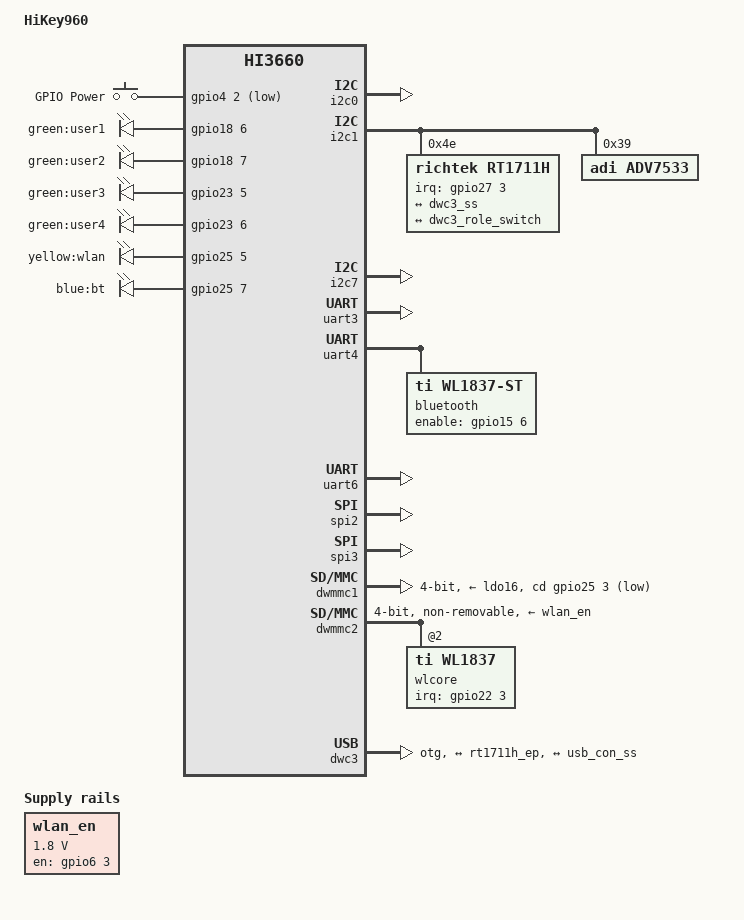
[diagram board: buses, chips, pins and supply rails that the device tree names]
/dts-v1/;
#include "hi3660.dtsi"
#include "hikey960-pinctrl.dtsi"
#include <dt-bindings/gpio/gpio.h>
#include <dt-bindings/input/input.h>
#include <dt-bindings/interrupt-controller/irq.h>
#include <dt-bindings/usb/pd.h>
/ {
	model = "HiKey960";
	compatible = "hisilicon,hi3660-hikey960", "hisilicon,hi3660";
	aliases {
		mshc1 = &dwmmc1;
		mshc2 = &dwmmc2;
		serial0 = &uart0;
		serial1 = &uart1;
		serial2 = &uart2;
		serial3 = &uart3;
		serial4 = &uart4;
		serial5 = &uart5;
		serial6 = &uart6;
	};
	chosen {
		stdout-path = "serial6:115200n8";
	};
	memory@0 {
		device_type = "memory";
		reg = <0x0 0x0 0x0 0x0>;
	};
	reserved-memory {
		#address-cells = <2>;
		#size-cells = <2>;
		ranges;
		ramoops@32000000 {
			compatible = "ramoops";
			reg = <0x0 0x32000000 0x0 0x00100000>;
			record-size = <0x00020000>;
			console-size = <0x00020000>;
			ftrace-size = <0x00020000>;
		};
	};
	reboot-mode-syscon@32100000 {
		compatible = "syscon", "simple-mfd";
		reg = <0x0 0x32100000 0x0 0x00001000>;
		reboot-mode {
			compatible = "syscon-reboot-mode";
			offset = <0x0>;
			mode-normal = <0x77665501>;
			mode-bootloader = <0x77665500>;
			mode-recovery = <0x77665502>;
		};
	};
	keys {
		compatible = "gpio-keys";
		pinctrl-names = "default";
		pinctrl-0 = <&pwr_key_pmx_func &pwr_key_cfg_func>;
		key-power {
			wakeup-source;
			gpios = <&gpio4 2 GPIO_ACTIVE_LOW>;
			label = "GPIO Power";
			linux,code = <KEY_POWER>;
		};
	};
	leds {
		compatible = "gpio-leds";
		led-user-1 {
			label = "green:user1";
			gpios = <&gpio18 6 0>;
			linux,default-trigger = "heartbeat";
		};
		led-user-2 {
			label = "green:user2";
			gpios = <&gpio18 7 0>;
			linux,default-trigger = "none";
		};
		led-user-3 {
			label = "green:user3";
			gpios = <&gpio23 5 0>;
			linux,default-trigger = "mmc0";
		};
		led-user-4 {
			label = "green:user4";
			gpios = <&gpio23 6 0>;
			panic-indicator;
			linux,default-trigger = "none";
		};
		led-wlan {
			label = "yellow:wlan";
			gpios = <&gpio25 5 0>;
			linux,default-trigger = "phy0tx";
			default-state = "off";
		};
		led-bt {
			label = "blue:bt";
			gpios = <&gpio25 7 0>;
			linux,default-trigger = "hci0-power";
			default-state = "off";
		};
	};
	pmic: pmic@fff34000 {
		compatible = "hisilicon,hi6421v530-pmic";
		reg = <0x0 0xfff34000 0x0 0x1000>;
		interrupt-controller;
		#interrupt-cells = <2>;
		regulators {
			ldo3: LDO3 {  
				regulator-name = "VOUT3_1V85";
				regulator-min-microvolt = <1800000>;
				regulator-max-microvolt = <2200000>;
				regulator-enable-ramp-delay = <120>;
			};
			ldo9: LDO9 {  
				regulator-name = "VOUT9_1V8_2V95";
				regulator-min-microvolt = <1750000>;
				regulator-max-microvolt = <3300000>;
				regulator-enable-ramp-delay = <240>;
			};
			ldo11: LDO11 {  
				regulator-name = "VOUT11_1V8_2V95";
				regulator-min-microvolt = <1750000>;
				regulator-max-microvolt = <3300000>;
				regulator-enable-ramp-delay = <240>;
			};
			ldo15: LDO15 {  
				regulator-name = "VOUT15_3V0";
				regulator-min-microvolt = <1750000>;
				regulator-max-microvolt = <3000000>;
				regulator-boot-on;
				regulator-always-on;
				regulator-enable-ramp-delay = <120>;
			};
			ldo16: LDO16 {  
				regulator-name = "VOUT16_2V95";
				regulator-min-microvolt = <1750000>;
				regulator-max-microvolt = <3000000>;
				regulator-enable-ramp-delay = <360>;
			};
		};
	};
	wlan_en: wlan-en-1-8v {
		compatible = "regulator-fixed";
		regulator-name = "wlan-en-regulator";
		regulator-min-microvolt = <1800000>;
		regulator-max-microvolt = <1800000>;
		gpio = <&gpio6 3 0>;
		startup-delay-us = <70000>;
		enable-active-high;
	};
	firmware {
		optee {
			compatible = "linaro,optee-tz";
			method = "smc";
		};
	};
};
&gpio0 {
	gpio-line-names =
		"",
		"TP901",  
		"[PMU0_SSI]",
		"[PMU1_SSI]",
		"[PMU2_SSI]",
		"[PMU0_CLKOUT]",
		"[JTAG_TCK]",
		"[JTAG_TMS]";
};
&gpio1 {
	gpio-line-names =
		"[JTAG_TRST_N]",
		"[JTAG_TDI]",
		"[JTAG_TDO]",
		"NC", "NC",
		"[I2C3_SCL]",
		"[I2C3_SDA]",
		"NC";
};
&gpio2 {
	gpio-line-names =
		"NC", "NC", "NC",
		"GPIO-J",  
		"GPIO_020_HDMI_SEL",
		"GPIO-L",  
		"GPIO_022_UFSBUCK_INT_N",
		"GPIO-G";  
};
&gpio3 {
	gpio-line-names =
		"[CSI0_MCLK]",  
		"[CSI1_MCLK]",  
		"NC",
		"[I2C2_SCL]",  
		"[I2C2_SDA]",  
		"[I2C3_SCL]",  
		"[I2C3_SDA]",  
		"NC";
};
&gpio4 {
	gpio-line-names =
		"NC", "NC",
		"PWR_BTN_N",  
		"GPIO_035_PMU2_EN",
		"GPIO_036_USB_HUB_RESET",
		"NC", "NC", "NC";
};
&gpio5 {
	gpio-line-names =
		"GPIO-H",  
		"GPIO_041_HDMI_PD",
		"TP904",  
		"TP905",  
		"NC", "NC",
		"GPIO_046_HUB_VDD33_EN",
		"GPIO_047_PMU1_EN";
};
&gpio6 {
	gpio-line-names =
		"NC", "NC", "NC",
		"GPIO_051_WIFI_EN",
		"GPIO-I",  
		"[SD_DAT1]",  
		"[SD_DAT2]",  
		"[UART1_RXD]";  
};
&gpio7 {
	gpio-line-names =
		"[UART1_TXD]",  
		"[UART0_CTS]",  
		"[UART0_RTS]",  
		"[UART0_RXD]",  
		"[UART0_TXD]",  
		"[SOC_BT_UART4_CTS_N]",
		"[SOC_BT_UART4_RTS_N]",
		"[SOC_BT_UART4_RXD]";
};
&gpio8 {
	gpio-line-names =
		"[SOC_BT_UART4_TXD]",
		"NC",
		"[PMU_HKADC_SSI]",
		"NC",
		"GPIO_068_SEL",
		"NC", "NC", "NC";
};
&gpio9 {
	gpio-line-names =
		"NC", "NC", "NC",
		"GPIO-K",  
		"NC", "NC", "NC", "NC";
};
&gpio10 {
	gpio-line-names = "NC", "NC", "NC", "NC", "NC", "NC", "NC", "NC";
};
&gpio11 {
	gpio-line-names =
		"NC",
		"[PCIE_PERST_N]",
		"NC", "NC", "NC", "NC", "NC", "NC";
};
&gpio12 {
	gpio-line-names = "NC", "NC", "NC", "", "", "", "", "NC";
};
&gpio13 {
	gpio-line-names = "NC", "NC", "NC", "NC", "NC", "NC", "NC", "NC";
};
&gpio14 {
	gpio-line-names = "NC", "NC", "NC", "NC", "NC", "NC", "NC", "NC";
};
&gpio15 {
	gpio-line-names =
		"NC", "NC", "NC", "NC", "NC", "NC",
		"GPIO_126_BT_EN",
		"TP902";  
};
&gpio16 {
	gpio-line-names = "", "", "", "", "", "", "", "";
};
&gpio17 {
	gpio-line-names = "", "", "", "", "", "", "", "";
};
&gpio18 {
	gpio-line-names =
		"[UFS_REF_CLK]",
		"[UFS_RST_N]",
		"[SPI1_SCLK]",  
		"[SPI1_DIN]",  
		"[SPI1_DOUT]",  
		"[SPI1_CS]",  
		"GPIO_150_USER_LED1",
		"GPIO_151_USER_LED2";
};
&gpio19 {
	gpio-line-names = "NC", "NC", "NC", "NC", "", "", "", "";
};
&gpio20 {
	gpio-line-names =
		"[SD_CLK]",
		"[SD_CMD]",
		"[SD_DATA0]",
		"[SD_DATA1]",
		"[SD_DATA2]",
		"[SD_DATA3]",
		"", "";
};
&gpio21 {
	gpio-line-names =
		"[WL_SDIO_CLK]",
		"[WL_SDIO_CMD]",
		"[WL_SDIO_DATA0]",
		"[WL_SDIO_DATA1]",
		"[WL_SDIO_DATA2]",
		"[WL_SDIO_DATA3]",
		"", "";
};
&gpio22 {
	gpio-line-names =
		"[GPIO_176_PMU_PWR_HOLD]",
		"NA",
		"[SYSCLK_EN]",
		"GPIO_179_WL_WAKEUP_AP",
		"GPIO_180_HDMI_INT",
		"NA",
		"GPIO-F",  
		"[I2C0_SCL]";  
};
&gpio23 {
	gpio-line-names =
		"[I2C0_SDA]",  
		"[I2C1_SCL]",  
		"[I2C1_SDA]",  
		"[I2C1_SCL]",  
		"[I2C1_SDA]",  
		"GPIO_189_USER_LED3",
		"GPIO_190_USER_LED4",
		"";
};
&gpio24 {
	gpio-line-names =
		"[PCM_DI]",  
		"[PCM_DO]",  
		"[PCM_CLK]",  
		"[PCM_FS]",  
		"[GPIO_196_I2S2_DI]",
		"[GPIO_197_I2S2_DO]",
		"[GPIO_198_I2S2_XCLK]",
		"[GPIO_199_I2S2_XFS]";
};
&gpio25 {
	gpio-line-names =
		"NC",
		"NC",
		"GPIO_202_VBUS_TYPEC",
		"GPIO_203_SD_DET",
		"GPIO_204_PMU12_IRQ_N",
		"GPIO_205_WIFI_ACTIVE",
		"GPIO_206_USBSW_SEL",
		"GPIO_207_BT_ACTIVE";
};
&gpio26 {
	gpio-line-names =
		"GPIO-A",  
		"GPIO-B",  
		"GPIO-C",  
		"GPIO-D",  
		"GPIO-E",  
		"[PCIE_CLKREQ_N]",
		"[PCIE_WAKE_N]",
		"[SPI0_CLK]";  
};
&gpio27 {
	gpio-line-names =
		"[SPI0_DIN]",  
		"[SPI0_DOUT]",  
		"[SPI0_CS]",  
		"GPIO_219_CC_INT",
		"NC",
		"NC",
		"[PMU_INT]",
		"";
};
&gpio28 {
	gpio-line-names =
		"", "", "", "", "", "", "", "";
};
&i2c0 {
	label = "LS-I2C0";
	status = "okay";
};
&i2c1 {
	status = "okay";
	rt1711h: rt1711h@4e {
		compatible = "richtek,rt1711h";
		reg = <0x4e>;
		status = "okay";
		interrupt-parent = <&gpio27>;
		interrupts = <3 IRQ_TYPE_LEVEL_LOW>;
		pinctrl-names = "default";
		pinctrl-0 = <&usb_cfg_func>;
		usb_con: connector {
			compatible = "usb-c-connector";
			label = "USB-C";
			data-role = "dual";
			power-role = "dual";
			try-power-role = "sink";
			source-pdos = <PDO_FIXED(5000, 500, PDO_FIXED_USB_COMM)>;
			sink-pdos = <PDO_FIXED(5000, 500, PDO_FIXED_USB_COMM)
				PDO_VAR(5000, 5000, 1000)>;
			op-sink-microwatt = <10000000>;
			ports {
				#address-cells = <1>;
				#size-cells = <0>;
				port@1 {
					reg = <1>;
					usb_con_ss: endpoint {
						remote-endpoint = <&dwc3_ss>;
					};
				};
			};
		};
		port {
			#address-cells = <1>;
			#size-cells = <0>;
			rt1711h_ep: endpoint@0 {
				reg = <0>;
				remote-endpoint = <&dwc3_role_switch>;
			};
		};
	};
	adv7533: adv7533@39 {
		status = "okay";
		compatible = "adi,adv7533";
		reg = <0x39>;
		adi,dsi-lanes = <4>;
		ports {
			#address-cells = <1>;
			#size-cells = <0>;
			port@0 {
				reg = <0>;
			};
			port@1 {
				reg = <1>;
			};
		};
	};
};
&i2c7 {
	label = "LS-I2C1";
	status = "okay";
};
&uart3 {
	label = "LS-UART0";
	status = "okay";
};
&uart4 {
	status = "okay";
	bluetooth {
		compatible = "ti,wl1837-st";
		enable-gpios = <&gpio15 6 GPIO_ACTIVE_HIGH>;
		max-speed = <3000000>;
	};
};
&uart6 {
	label = "LS-UART1";
	status = "okay";
};
&spi2 {
	label = "LS-SPI0";
	status = "okay";
};
&spi3 {
	label = "HS-SPI1";
	status = "okay";
};
&dwmmc1 {
	bus-width = <0x4>;
	cap-sd-highspeed;
	sd-uhs-sdr12;
	sd-uhs-sdr25;
	sd-uhs-sdr50;
	sd-uhs-sdr104;
	disable-wp;
	cd-gpios = <&gpio25 3 GPIO_ACTIVE_LOW>;
	pinctrl-names = "default";
	pinctrl-0 = <&sd_pmx_func
		     &sd_clk_cfg_func
		     &sd_cfg_func>;
	vmmc-supply = <&ldo16>;
	vqmmc-supply = <&ldo9>;
	status = "okay";
};
&dwmmc2 {  
	bus-width = <0x4>;
	non-removable;
	broken-cd;
	cap-power-off-card;
	pinctrl-names = "default";
	pinctrl-0 = <&sdio_pmx_func
		     &sdio_clk_cfg_func
		     &sdio_cfg_func>;
	vmmc-supply = <&wlan_en>;
	status = "okay";
	wlcore: wlcore@2 {
		compatible = "ti,wl1837";
		reg = <2>;       
		interrupt-parent = <&gpio22>;
		interrupts = <3 IRQ_TYPE_EDGE_RISING>;
	};
};
&dwc3 {  
	dr_mode = "otg";
	maximum-speed = "super-speed";
	phy_type = "utmi";
	snps,dis-del-phy-power-chg-quirk;
	snps,lfps_filter_quirk;
	snps,dis_u2_susphy_quirk;
	snps,dis_u3_susphy_quirk;
	snps,tx_de_emphasis_quirk;
	snps,tx_de_emphasis = <1>;
	snps,dis_enblslpm_quirk;
	snps,gctl-reset-quirk;
	usb-role-switch;
	role-switch-default-mode = "host";
	port {
		#address-cells = <1>;
		#size-cells = <0>;
		dwc3_role_switch: endpoint@0 {
			reg = <0>;
			remote-endpoint = <&rt1711h_ep>;
		};
		dwc3_ss: endpoint@1 {
			reg = <1>;
			remote-endpoint = <&usb_con_ss>;
		};
	};
};
